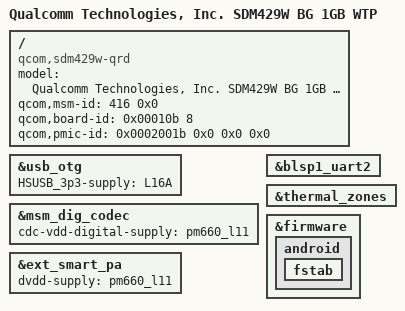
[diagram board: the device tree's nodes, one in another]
/*
 * Copyright (c) 2019, The Linux Foundation. All rights reserved.
 *
 * This program is free software; you can redistribute it and/or modify
 * it under the terms of the GNU General Public License version 2 and
 * only version 2 as published by the Free Software Foundation.
 *
 * This program is distributed in the hope that it will be useful,
 * but WITHOUT ANY WARRANTY; without even the implied warranty of
 * MERCHANTABILITY or FITNESS FOR A PARTICULAR PURPOSE.  See the
 * GNU General Public License for more details.
 */

/dts-v1/;

#include "sdm429-spyro.dtsi"
#include "sdm429-spyro-qrd-evt.dtsi"
/ {
	model = "Qualcomm Technologies, Inc. SDM429W BG 1GB WTP";
	compatible = "qcom,sdm429w-qrd", "qcom,sdm429w", "qcom,qrd";
	qcom,msm-id = <416 0x0>;
	qcom,board-id = <0x00010b 8>;
	qcom,pmic-id = <0x0002001b 0x0 0x0 0x0>;
};

&usb_otg {
	HSUSB_3p3-supply = <&L16A>;
};

&msm_dig_codec {
	cdc-vdd-digital-supply = <&pm660_l11>;
};

&ext_smart_pa {
	dvdd-supply = <&pm660_l11>;
};

&blsp1_uart2 {
	status = "okay";
};

&thermal_zones {
	/delete-node/ emmc-therm-adc;
	/delete-node/ aoss0-lowf;
	/delete-node/ mdm-core-lowf;
	/delete-node/ lpass-lowf;
	/delete-node/ camera-lowf;
	/delete-node/ cpuss1-lowf;
	/delete-node/ apc1-cpu0-lowf;
	/delete-node/ apc1-cpu1-lowf;
	/delete-node/ apc1-cpu2-lowf;
	/delete-node/ apc1-cpu3-lowf;
	/delete-node/ cpuss0-lowf;
	/delete-node/ gpu-lowf;
};

&firmware {
	android {
		fstab {
	/delete-node/ system ;
		};
	};
};
